# Spinlock register map
Vendor: Texas Instruments
Peripheral module from a debugger description file (folder omap5430_ES2_PUBLIC).
Registers are 32-bit, access per field, reset 0x0 unless marked. A register's access mark holds for its fields unless they carry their own. Offsets are as the file gives them; lines under a group give offsets from that group; [hi:lo] are bit positions; {n}, {i} and the like mark numbered series; 'fields as' and 'values as' point back to an identical list; <NAME> marks a mode.

## Spinlock
0x00 SPINLOCK_REVISION ro reset not defined — This register contains the IP revision code
  [31:0] REVISION — IP revision
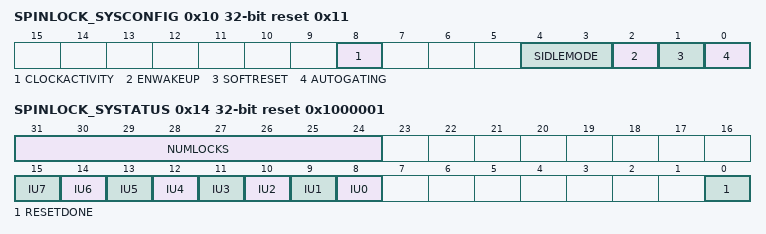
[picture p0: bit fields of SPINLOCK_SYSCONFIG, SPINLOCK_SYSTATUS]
0x10 SPINLOCK_SYSCONFIG reset 0x11 — This register controls the various parameters of the L4_CFG interface. Note that most fields are read-only.
  [8] CLOCKACTIVITY ro — Indicates whether the module requires the interface clock when in IDLE mode.
    0=IDLE_0 (Interface clock is not required by the module during IDLE mode and may be switched off.); 1=CLOCKACTIVITY_1_r (Interface clock is required by the module, even during idle mode.)
  [4:3] SIDLEMODE ro — Slave interface power management (IDLE request/acknowledgement control).
    0=IDLE_0 (Force-idle. IDLE request is acknowledged unconditionally and immediately.); 1=IDLE_1 (No-idle. IDLE request is never acknowledged.); 2=IDLE_2 (Smart-idle. IDLE request acknowledgement is based on the internal module activity.); 3=Reserved._Do_not_use
  [2] ENWAKEUP ro — Asynchronous wakeup gereration.
    0=Wakeup_generation_is_disabled; 1=Wakeup_generation_is_enabled
  [1] SOFTRESET wo — Module software reset.
    0=No_action; 1=Start_soft_reset_sequence
  [0] AUTOGATING ro — Internal interface clock gating strategy.
    0=L4_CFG_0 (Interface clock is not gated when the L4_CFG interface is idle.); 1=L4_CFG_1 (Automatic internal interface clock gating strategy is applied, based on the L4_CFG interface activity.)
0x14 SPINLOCK_SYSTATUS ro reset 0x1000001 — This register provides status information about this instance of the Spinlock module.
  [31:24] NUMLOCKS — Number of lock registers implemeted.
    1=This_instance_has_32_lock_registers; 2=This_instance_has_64_lock_registers; 4=This_instance_has_128_lock_registers; 8=This_instance_has_256_lock_registers
  [n+8] IU{n} (n=1..7) — In-Use flag {n}. Reads always return 0.
  [8] IU0 — In-Use flag 0, covering lock registers 0 - 31.
    0=IU0_0_r (All lock registers 0 31 are in the Not Taken state.); 1=IU0_1_r (At least one of the lock registers 0 31 is in the Taken state.)
  [0] RESETDONE — Reset done status.
    0=Reset_in_progress; 1=Reset_is_completed
{0x800+4i} SPINLOCK_LOCK_REG_i_{i} (i=0..31) — This register contains the state of one lock.
  [0] TAKEN rw — Lock State
    0=TAKEN_0_r (Lock was previously Not Taken (free). The requester is granted the lock.); 0=Set_the_lock_to_Not_Taken_(free); 1=TAKEN_1_r (Lock was previously Taken. The requester is not granted the lock and must retry.); 1=No_update_to_the_lock_value
